VERSION ""

NS_ :

BS_: 500

BU_: Vector__XXX

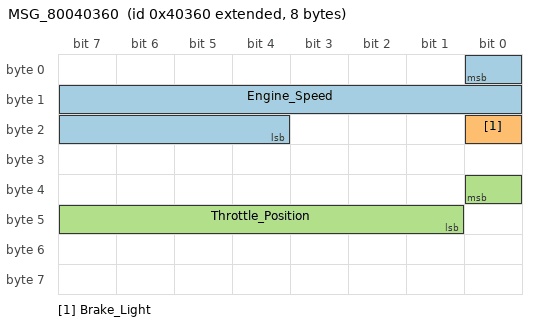
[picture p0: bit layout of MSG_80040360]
BO_ 2147746656 MSG_80040360: 8 Vector__XXX
 SG_ Engine_Speed : 0|13@0+ (1,0) [0|8191] "rpm" Vector__XXX
 SG_ Brake_Light : 16|1@0+ (1,0) [0|0] "" Vector__XXX
 SG_ Throttle_Position : 32|8@0+ (0.31348,-10.6583) [-10.65830721|69.2789968652] "%" Vector__XXX

BO_ 2165571616 MSG_81140020: 8 Vector__XXX
 SG_ Wheel_Speed_4_kph : 0|15@0+ (0.01,0) [0|327.67] "km/h" Vector__XXX
 SG_ Wheel_Speed_4_mph : 0|15@0+ (0.00621,0) [0|203.48307] "mph" Vector__XXX
 SG_ Wheel_Speed_3_kph : 16|15@0+ (0.01,0) [0|327.67] "km/h" Vector__XXX
 SG_ Wheel_Speed_3_mph : 16|15@0+ (0.00621,0) [0|203.48307] "mph" Vector__XXX

BO_ 2221146720 MSG_84640260: 8 Vector__XXX
 SG_ Accelerator_Pedal_Position : 56|8@0+ (0.502513,0) [0|128.140703518] "" Vector__XXX

BO_ 2300313968 MSG_891C0170: 8 Vector__XXX
 SG_ Indicated_Vehicle_Speed_kph : 0|15@0+ (0.01,0) [0|327.67] "km/h" Vector__XXX
 SG_ Indicated_Vehicle_Speed_mph : 0|15@0+ (0.00621,0) [0|203.48307] "mph" Vector__XXX

BO_ 2506883440 MSG_956C0170: 8 Vector__XXX
 SG_ Wheel_Speed_2_kph : 0|15@0+ (0.01,0) [0|327.67] "km/h" Vector__XXX
 SG_ Wheel_Speed_2_mph : 0|15@0+ (0.00621,0) [0|203.48307] "mph" Vector__XXX
 SG_ Wheel_Speed_1_kph : 16|15@0+ (0.01,0) [0|327.67] "km/h" Vector__XXX
 SG_ Wheel_Speed_1_mph : 16|15@0+ (0.00621,0) [0|203.48307] "mph" Vector__XXX
 SG_ Brake_Position : 40|8@0+ (1,0) [0|255] "%" Vector__XXX

BO_ 2511340128 MSG_95B00260: 8 Vector__XXX
 SG_ Coolant_Temperature : 0|8@0+ (1,-60) [-60|195] "��C" Vector__XXX

BO_ 2524447296 MSG_96780240: 5 Vector__XXX
 SG_ Steering_Angle : 24|14@0+ (0.1,-778) [-778|860.3] "��" Vector__XXX
